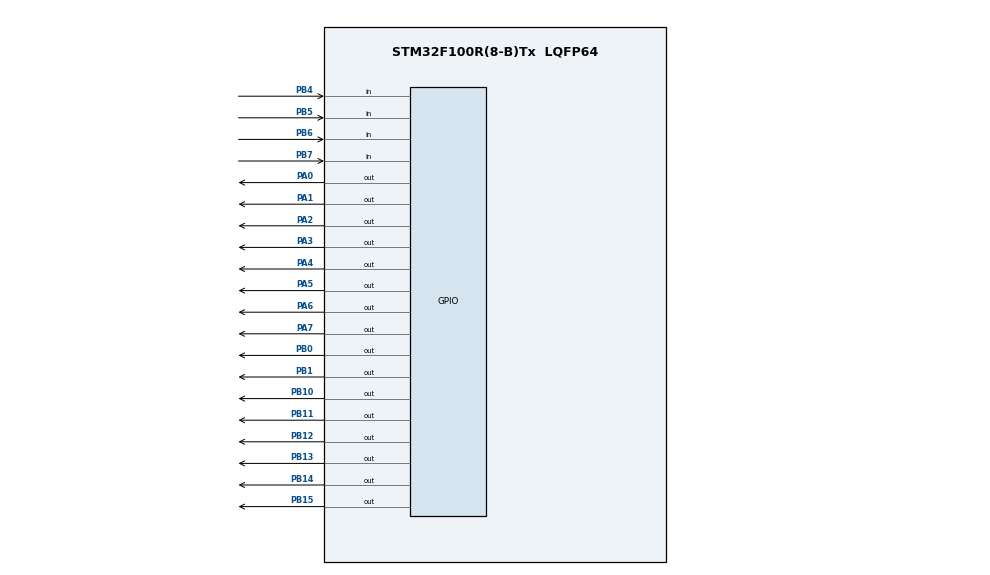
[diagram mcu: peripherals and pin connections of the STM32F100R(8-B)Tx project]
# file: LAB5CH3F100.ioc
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Mcu.Family=STM32F1
Mcu.Name=STM32F100R(8-B)Tx
Mcu.Package=LQFP64
NVIC.PriorityGroup=NVIC_PRIORITYGROUP_4
NVIC.TIM6_DAC_IRQn=true\:0\:0\:false\:false\:true\:true\:true
PA0-WKUP.GPIO_Speed=GPIO_SPEED_FREQ_LOW
PA0-WKUP.Signal=GPIO_Output
PA1.GPIO_Speed=GPIO_SPEED_FREQ_LOW
PA1.Signal=GPIO_Output
PA13.Mode=Serial_Wire
PA13.Signal=SYS_JTMS-SWDIO
PA14.Mode=Serial_Wire
PA14.Signal=SYS_JTCK-SWCLK
PA2.GPIO_Speed=GPIO_SPEED_FREQ_LOW
PA2.Signal=GPIO_Output
PA3.GPIO_Speed=GPIO_SPEED_FREQ_LOW
PA3.Signal=GPIO_Output
PA4.GPIO_Speed=GPIO_SPEED_FREQ_LOW
PA4.PinState=GPIO_PIN_RESET
PA4.Signal=GPIO_Output
PA5.GPIO_Speed=GPIO_SPEED_FREQ_LOW
PA5.Signal=GPIO_Output
PA6.GPIO_Speed=GPIO_SPEED_FREQ_LOW
PA6.Signal=GPIO_Output
PA7.GPIO_Speed=GPIO_SPEED_FREQ_LOW
PA7.Signal=GPIO_Output
PB0.GPIO_Speed=GPIO_SPEED_FREQ_HIGH
PB0.Signal=GPIO_Output
PB1.GPIO_Speed=GPIO_SPEED_FREQ_HIGH
PB1.Signal=GPIO_Output
PB10.GPIO_Speed=GPIO_SPEED_FREQ_HIGH
PB10.Signal=GPIO_Output
PB11.GPIO_Speed=GPIO_SPEED_FREQ_HIGH
PB11.Signal=GPIO_Output
PB12.GPIO_ModeDefaultOutputPP=GPIO_MODE_OUTPUT_OD
PB12.GPIO_Speed=GPIO_SPEED_FREQ_HIGH
PB12.PinState=GPIO_PIN_RESET
PB12.Signal=GPIO_Output
PB13.GPIO_ModeDefaultOutputPP=GPIO_MODE_OUTPUT_OD
PB13.GPIO_Speed=GPIO_SPEED_FREQ_HIGH
PB13.PinState=GPIO_PIN_RESET
PB13.Signal=GPIO_Output
PB14.GPIO_ModeDefaultOutputPP=GPIO_MODE_OUTPUT_OD
PB14.GPIO_Speed=GPIO_SPEED_FREQ_HIGH
PB14.PinState=GPIO_PIN_RESET
PB14.Signal=GPIO_Output
PB15.GPIO_ModeDefaultOutputPP=GPIO_MODE_OUTPUT_OD
PB15.GPIO_Speed=GPIO_SPEED_FREQ_HIGH
PB15.PinState=GPIO_PIN_RESET
PB15.Signal=GPIO_Output
PB4.GPIO_PuPd=GPIO_PULLUP
PB4.Signal=GPIO_Input
PB5.GPIO_PuPd=GPIO_PULLUP
PB5.Signal=GPIO_Input
PB6.GPIO_PuPd=GPIO_PULLUP
PB6.Signal=GPIO_Input
PB7.GPIO_PuPd=GPIO_PULLUP
PB7.Signal=GPIO_Input
PD0-OSC_IN.Mode=HSE-External-Oscillator
PD0-OSC_IN.Signal=RCC_OSC_IN
PD1-OSC_OUT.Mode=HSE-External-Oscillator
PD1-OSC_OUT.Signal=RCC_OSC_OUT
ProjectManager.HeapSize=0x200
ProjectManager.StackSize=0x400
ProjectManager.TargetToolchain=EWARM V8
RCC.APB1Freq_Value=8000000
RCC.APB2Freq_Value=8000000
TIM6.Period=200
TIM6.Prescaler=65535
VP_TIM6_VS_ClockSourceINT.Mode=Enable_Timer
board=custom

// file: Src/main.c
/* USER CODE BEGIN Header */
/**
  ******************************************************************************
  * @file           : main.c
  * @brief          : Main program body
  ******************************************************************************
  ** This notice applies to any and all portions of this file
  * that are not between comment pairs USER CODE BEGIN and
  * USER CODE END. Other portions of this file, whether
  * inserted by the user or by software development tools
  * are owned by their respective copyright owners.
  *
  * COPYRIGHT(c) 2019 STMicroelectronics
  *
  * Redistribution and use in source and binary forms, with or without modification,
  * are permitted provided that the following conditions are met:
  *   1. Redistributions of source code must retain the above copyright notice,
  *      this list of conditions and the following disclaimer.
  *   2. Redistributions in binary form must reproduce the above copyright notice,
  *      this list of conditions and the following disclaimer in the documentation
  *      and/or other materials provided with the distribution.
  *   3. Neither the name of STMicroelectronics nor the names of its contributors
  *      may be used to endorse or promote products derived from this software
  *      without specific prior written permission.
  *
  * THIS SOFTWARE IS PROVIDED BY THE COPYRIGHT HOLDERS AND CONTRIBUTORS "AS IS"
  * AND ANY EXPRESS OR IMPLIED WARRANTIES, INCLUDING, BUT NOT LIMITED TO, THE
  * IMPLIED WARRANTIES OF MERCHANTABILITY AND FITNESS FOR A PARTICULAR PURPOSE ARE
  * DISCLAIMED. IN NO EVENT SHALL THE COPYRIGHT HOLDER OR CONTRIBUTORS BE LIABLE
  * FOR ANY DIRECT, INDIRECT, INCIDENTAL, SPECIAL, EXEMPLARY, OR CONSEQUENTIAL
  * DAMAGES (INCLUDING, BUT NOT LIMITED TO, PROCUREMENT OF SUBSTITUTE GOODS OR
  * SERVICES; LOSS OF USE, DATA, OR PROFITS; OR BUSINESS INTERRUPTION) HOWEVER
  * CAUSED AND ON ANY THEORY OF LIABILITY, WHETHER IN CONTRACT, STRICT LIABILITY,
  * OR TORT (INCLUDING NEGLIGENCE OR OTHERWISE) ARISING IN ANY WAY OUT OF THE USE
  * OF THIS SOFTWARE, EVEN IF ADVISED OF THE POSSIBILITY OF SUCH DAMAGE.
  *
  ******************************************************************************
  */
/* USER CODE END Header */

#include "main.h"

/* USER CODE BEGIN Includes */
#include "global.h"
/* USER CODE END Includes */

void SystemClock_Config(void);
static void MX_GPIO_Init(void);
static void MX_TIM6_Init(void);

int main(void)
{

  /* MCU Configuration--------------------------------------------------------*/

  /* Reset of all peripherals, Initializes the Flash interface and the Systick. */
  HAL_Init();

  /* Configure the system clock */
  SystemClock_Config();

  /* Initialize all configured peripherals */
  MX_GPIO_Init();
  MX_TIM6_Init();
  /* USER CODE BEGIN 2 */
LL_TIM_EnableIT_UPDATE(TIM6);
   LL_TIM_EnableCounter(TIM6);
   ledp = 0;
   //butch=1;
  /* USER CODE END 2 */

  /* Infinite loop */
  /* USER CODE BEGIN WHILE */

	//(GPIOA->IDR & GPIO_PIN_0) == 1
  while (1)
  {
    /* USER CODE END WHILE */

    /* USER CODE BEGIN 3 */
    //select((ledp)%4);//blink digits
    //show((ledp++)%4);//- blink segments
    //clearseg();
  }
  /* USER CODE END 3 */
}

void SystemClock_Config(void)
{
  LL_RCC_HSI_SetCalibTrimming(16);
  LL_RCC_HSI_Enable();

   /* Wait till HSI is ready */
  while(LL_RCC_HSI_IsReady() != 1)
  {

  }
  LL_RCC_SetAHBPrescaler(LL_RCC_SYSCLK_DIV_1);
  LL_RCC_SetAPB1Prescaler(LL_RCC_APB1_DIV_1);
  LL_RCC_SetAPB2Prescaler(LL_RCC_APB2_DIV_1);
  LL_RCC_SetSysClkSource(LL_RCC_SYS_CLKSOURCE_HSI);

   /* Wait till System clock is ready */
  while(LL_RCC_GetSysClkSource() != LL_RCC_SYS_CLKSOURCE_STATUS_HSI)
  {

  }
  LL_Init1msTick(8000000);
  LL_SYSTICK_SetClkSource(LL_SYSTICK_CLKSOURCE_HCLK);
  LL_SetSystemCoreClock(8000000);
}

static void MX_TIM6_Init(void)
{

  LL_TIM_InitTypeDef TIM_InitStruct = {0};

  /* Peripheral clock enable */
  LL_APB1_GRP1_EnableClock(LL_APB1_GRP1_PERIPH_TIM6);

  /* TIM6 interrupt Init */
  NVIC_SetPriority(TIM6_DAC_IRQn, NVIC_EncodePriority(NVIC_GetPriorityGrouping(),0, 0));
  NVIC_EnableIRQ(TIM6_DAC_IRQn);

  TIM_InitStruct.Prescaler = 1;
  TIM_InitStruct.CounterMode = LL_TIM_COUNTERMODE_UP;
  TIM_InitStruct.Autoreload = 200;
  LL_TIM_Init(TIM6, &TIM_InitStruct);
  LL_TIM_DisableARRPreload(TIM6);
  LL_TIM_SetTriggerOutput(TIM6, LL_TIM_TRGO_RESET);
  LL_TIM_DisableMasterSlaveMode(TIM6);

}

static void MX_GPIO_Init(void)
{
  GPIO_InitTypeDef GPIO_InitStruct = {0};

  /* GPIO Ports Clock Enable */
  __HAL_RCC_GPIOD_CLK_ENABLE();
  __HAL_RCC_GPIOA_CLK_ENABLE();
  __HAL_RCC_GPIOB_CLK_ENABLE();

  /*Configure GPIO pin Output Level */
  HAL_GPIO_WritePin(GPIOA, GPIO_PIN_0|GPIO_PIN_1|GPIO_PIN_2|GPIO_PIN_3
                          |GPIO_PIN_4|GPIO_PIN_5|GPIO_PIN_6|GPIO_PIN_7, GPIO_PIN_RESET);

  /*Configure GPIO pin Output Level */
  HAL_GPIO_WritePin(GPIOB, GPIO_PIN_0|GPIO_PIN_1|GPIO_PIN_10|GPIO_PIN_11
                          |GPIO_PIN_12|GPIO_PIN_13|GPIO_PIN_14|GPIO_PIN_15, GPIO_PIN_RESET);

  /*Configure GPIO pins : PA0 PA1 PA2 PA3
                           PA4 PA5 PA6 PA7 */
  GPIO_InitStruct.Pin = GPIO_PIN_0|GPIO_PIN_1|GPIO_PIN_2|GPIO_PIN_3
                          |GPIO_PIN_4|GPIO_PIN_5|GPIO_PIN_6|GPIO_PIN_7;
  GPIO_InitStruct.Mode = GPIO_MODE_OUTPUT_PP;
  GPIO_InitStruct.Pull = GPIO_NOPULL;
  GPIO_InitStruct.Speed = GPIO_SPEED_FREQ_LOW;
  HAL_GPIO_Init(GPIOA, &GPIO_InitStruct);

  /*Configure GPIO pins : PB0 PB1 PB10 PB11 */
  GPIO_InitStruct.Pin = GPIO_PIN_0|GPIO_PIN_1|GPIO_PIN_10|GPIO_PIN_11;
  GPIO_InitStruct.Mode = GPIO_MODE_OUTPUT_PP;
  GPIO_InitStruct.Pull = GPIO_NOPULL;
  GPIO_InitStruct.Speed = GPIO_SPEED_FREQ_HIGH;
  HAL_GPIO_Init(GPIOB, &GPIO_InitStruct);

  /*Configure GPIO pins : PB12 PB13 PB14 PB15 */
  GPIO_InitStruct.Pin = GPIO_PIN_12|GPIO_PIN_13|GPIO_PIN_14|GPIO_PIN_15;
  GPIO_InitStruct.Mode = GPIO_MODE_OUTPUT_OD;
  GPIO_InitStruct.Pull = GPIO_NOPULL;
  GPIO_InitStruct.Speed = GPIO_SPEED_FREQ_HIGH;
  HAL_GPIO_Init(GPIOB, &GPIO_InitStruct);

  /*Configure GPIO pins : PB4 PB5 PB6 PB7 */
  GPIO_InitStruct.Pin = GPIO_PIN_4|GPIO_PIN_5|GPIO_PIN_6|GPIO_PIN_7;
  GPIO_InitStruct.Mode = GPIO_MODE_INPUT;
  GPIO_InitStruct.Pull = GPIO_PULLUP;
  HAL_GPIO_Init(GPIOB, &GPIO_InitStruct);

}

void Error_Handler(void)
{
}

/************************ (C) COPYRIGHT STMicroelectronics *****END OF FILE****/
